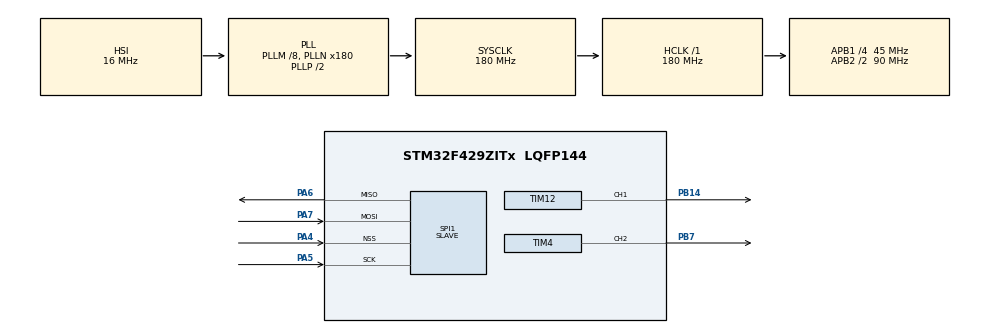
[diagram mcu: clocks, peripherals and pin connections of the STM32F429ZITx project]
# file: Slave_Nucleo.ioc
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Mcu.Family=STM32F4
Mcu.Name=STM32F429ZITx
Mcu.Package=LQFP144
NVIC.PriorityGroup=NVIC_PRIORITYGROUP_4
NVIC.SPI1_IRQn=true\:0\:0\:false\:false\:true\:true\:true\:true
PA13.Mode=Serial_Wire
PA13.Signal=SYS_JTMS-SWDIO
PA14.Mode=Serial_Wire
PA14.Signal=SYS_JTCK-SWCLK
PA4.Mode=NSS_Signal_Hard_Input
PA4.Signal=SPI1_NSS
PA5.Mode=Full_Duplex_Slave
PA5.Signal=SPI1_SCK
PA6.Mode=Full_Duplex_Slave
PA6.Signal=SPI1_MISO
PA7.Mode=Full_Duplex_Slave
PA7.Signal=SPI1_MOSI
PB14.Signal=S_TIM12_CH1
PB7.Signal=S_TIM4_CH2
PH0/OSC_IN.Mode=HSE-External-Oscillator
PH0/OSC_IN.Signal=RCC_OSC_IN
PH1/OSC_OUT.Mode=HSE-External-Oscillator
PH1/OSC_OUT.Signal=RCC_OSC_OUT
ProjectManager.HeapSize=0x200
ProjectManager.StackSize=0x400
ProjectManager.TargetToolchain=STM32CubeIDE
RCC.48MHZClocksFreq_Value=90000000
RCC.AHBFreq_Value=180000000
RCC.APB1CLKDivider=RCC_HCLK_DIV4
RCC.APB1Freq_Value=45000000
RCC.APB1TimFreq_Value=90000000
RCC.APB2CLKDivider=RCC_HCLK_DIV2
RCC.APB2Freq_Value=90000000
RCC.APB2TimFreq_Value=180000000
RCC.CortexFreq_Value=180000000
RCC.HCLKFreq_Value=180000000
RCC.HSE_VALUE=25000000
RCC.HSI_VALUE=16000000
RCC.LSE_VALUE=32768
RCC.PLLM=8
RCC.PLLN=180
RCC.SYSCLKFreq_VALUE=180000000
RCC.SYSCLKSource=RCC_SYSCLKSOURCE_PLLCLK
RCC.VCOOutputFreq_Value=360000000
SH.S_TIM12_CH1.0=TIM12_CH1,PWM Generation1 CH1
SH.S_TIM4_CH2.0=TIM4_CH2,PWM Generation2 CH2
SPI1.CLKPolarity=SPI_POLARITY_HIGH
SPI1.DataSize=SPI_DATASIZE_16BIT
SPI1.Direction=SPI_DIRECTION_2LINES
SPI1.Mode=SPI_MODE_SLAVE
SPI1.TIMode=SPI_TIMODE_DISABLE
SPI1.VirtualNSS=VM_NSSHARD
SPI1.VirtualType=VM_SLAVE
TIM12.Channel-PWM\ Generation1\ CH1=TIM_CHANNEL_1
TIM12.Period=100-1
TIM12.Prescaler=18-1
TIM4.Channel-PWM\ Generation2\ CH2=TIM_CHANNEL_2
TIM4.Period=100-1
TIM4.Prescaler=18-1
VP_TIM4_VS_ClockSourceINT.Mode=Internal
board=custom

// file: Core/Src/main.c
/* USER CODE BEGIN Header */
/**
 ******************************************************************************
 * @file           : main.c
 * @brief          : Main program body
 ******************************************************************************
 * @attention
 *
 * Copyright (c) 2023 STMicroelectronics.
 * All rights reserved.
 *
 * This software is licensed under terms that can be found in the LICENSE file
 * in the root directory of this software component.
 * If no LICENSE file comes with this software, it is provided AS-IS.
 *
 ******************************************************************************
 */
/* USER CODE END Header */
#include "main.h"
#include "spi.h"
#include "tim.h"
#include "gpio.h"

/* USER CODE BEGIN PV */
extern volatile uint8_t data_rx[3];
/* USER CODE END PV */

void SystemClock_Config(void);

int main(void)
{

  /* MCU Configuration--------------------------------------------------------*/

  /* Reset of all peripherals, Initializes the Flash interface and the Systick. */
  HAL_Init();

  /* Configure the system clock */
  SystemClock_Config();

  /* Initialize all configured peripherals */
  MX_GPIO_Init();
  MX_SPI1_Init();
  MX_TIM4_Init();
  MX_TIM12_Init();
  /* USER CODE BEGIN 2 */
	HAL_TIM_PWM_Start(&htim4, TIM_CHANNEL_2);
	HAL_TIM_PWM_Start(&htim12, TIM_CHANNEL_1);
	HAL_SPI_Receive_IT(&hspi1, (uint8_t*) data_rx, 3);
  /* USER CODE END 2 */

  /* Infinite loop */
  /* USER CODE BEGIN WHILE */
	while (1) {
		if (HAL_SPI_GetState(&hspi1) != HAL_SPI_STATE_READY) {
			HAL_SPI_Receive_IT(&hspi1, (uint8_t*) data_rx, 3);
		}
		HAL_SPI_Receive_IT(&hspi1, (uint8_t*) data_rx, 3);

    /* USER CODE END WHILE */

	}
}

void SystemClock_Config(void)
{
  RCC_OscInitTypeDef RCC_OscInitStruct = {0};
  RCC_ClkInitTypeDef RCC_ClkInitStruct = {0};

  /** Configure the main internal regulator output voltage
  */
  __HAL_RCC_PWR_CLK_ENABLE();
  __HAL_PWR_VOLTAGESCALING_CONFIG(PWR_REGULATOR_VOLTAGE_SCALE1);

  /** Initializes the RCC Oscillators according to the specified parameters
  * in the RCC_OscInitTypeDef structure.
  */
  RCC_OscInitStruct.OscillatorType = RCC_OSCILLATORTYPE_HSI;
  RCC_OscInitStruct.HSIState = RCC_HSI_ON;
  RCC_OscInitStruct.HSICalibrationValue = RCC_HSICALIBRATION_DEFAULT;
  RCC_OscInitStruct.PLL.PLLState = RCC_PLL_ON;
  RCC_OscInitStruct.PLL.PLLSource = RCC_PLLSOURCE_HSI;
  RCC_OscInitStruct.PLL.PLLM = 8;
  RCC_OscInitStruct.PLL.PLLN = 180;
  RCC_OscInitStruct.PLL.PLLP = RCC_PLLP_DIV2;
  RCC_OscInitStruct.PLL.PLLQ = 4;
  if (HAL_RCC_OscConfig(&RCC_OscInitStruct) != HAL_OK)
  {
    Error_Handler();
  }

  /** Activate the Over-Drive mode
  */
  if (HAL_PWREx_EnableOverDrive() != HAL_OK)
  {
    Error_Handler();
  }

  /** Initializes the CPU, AHB and APB buses clocks
  */
  RCC_ClkInitStruct.ClockType = RCC_CLOCKTYPE_HCLK|RCC_CLOCKTYPE_SYSCLK
                              |RCC_CLOCKTYPE_PCLK1|RCC_CLOCKTYPE_PCLK2;
  RCC_ClkInitStruct.SYSCLKSource = RCC_SYSCLKSOURCE_PLLCLK;
  RCC_ClkInitStruct.AHBCLKDivider = RCC_SYSCLK_DIV1;
  RCC_ClkInitStruct.APB1CLKDivider = RCC_HCLK_DIV4;
  RCC_ClkInitStruct.APB2CLKDivider = RCC_HCLK_DIV2;

  if (HAL_RCC_ClockConfig(&RCC_ClkInitStruct, FLASH_LATENCY_5) != HAL_OK)
  {
    Error_Handler();
  }
}

void Error_Handler(void)
{
	__disable_irq();
	while (1) {
	}
}
